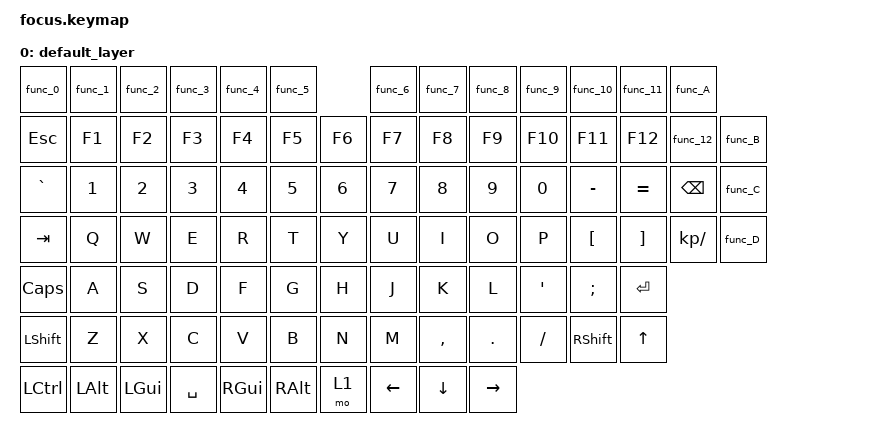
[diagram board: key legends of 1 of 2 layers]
#include <behaviors.dtsi>
#include <dt-bindings/zmk/keys.h>
#include <dt-bindings/zmk/bt.h>

/ {
    macros {
        zed_em_kay: zed_em_kay {
            compatible = "zmk,behavior-macro";
            #binding-cells = <0>;
            bindings
                = <&macro_press &kp LGUI>
                , <&macro_tap &kp N>
                , <&macro_release &kp LGUI>
                ;
        };
        func_0: func_0 {
            compatible = "zmk,behavior-macro";
            #binding-cells = <0>;
            bindings
                = <&macro_press &kp LSHIFT>
                , <&macro_press &kp LCTRL>
                , <&macro_press &kp LALT>
                , <&macro_tap &kp R>
                , <&macro_release &kp LSHIFT>
                , <&macro_release &kp LCTRL>
                , <&macro_release &kp LALT>
                ;
        };
        func_1: func_1 {
            compatible = "zmk,behavior-macro";
            #binding-cells = <0>;
            bindings
                = <&macro_press &kp LSHIFT>
                , <&macro_press &kp LCTRL>
                , <&macro_press &kp LALT>
                , <&macro_tap &kp T>
                , <&macro_release &kp LSHIFT>
                , <&macro_release &kp LCTRL>
                , <&macro_release &kp LALT>
                ;
        };
        func_2: func_2 {
            compatible = "zmk,behavior-macro";
            #binding-cells = <0>;
            bindings
                = <&macro_press &kp LSHIFT>
                , <&macro_press &kp LCTRL>
                , <&macro_press &kp LALT>
                , <&macro_tap &kp Y>
                , <&macro_release &kp LSHIFT>
                , <&macro_release &kp LCTRL>
                , <&macro_release &kp LALT>
                ;
        };
        func_3: func_3 {
            compatible = "zmk,behavior-macro";
            #binding-cells = <0>;
            bindings
                = <&macro_press &kp LSHIFT>
                , <&macro_press &kp LCTRL>
                , <&macro_press &kp LALT>
                , <&macro_tap &kp U>
                , <&macro_release &kp LSHIFT>
                , <&macro_release &kp LCTRL>
                , <&macro_release &kp LALT>
                ;
        };
        func_4: func_4 {
            compatible = "zmk,behavior-macro";
            #binding-cells = <0>;
            bindings
                = <&macro_press &kp LSHIFT>
                , <&macro_press &kp LCTRL>
                , <&macro_press &kp LALT>
                , <&macro_tap &kp I>
                , <&macro_release &kp LSHIFT>
                , <&macro_release &kp LCTRL>
                , <&macro_release &kp LALT>
                ;
        };
        func_5: func_5 {
            compatible = "zmk,behavior-macro";
            #binding-cells = <0>;
            bindings
                = <&macro_press &kp LSHIFT>
                , <&macro_press &kp LCTRL>
                , <&macro_press &kp LALT>
                , <&macro_tap &kp O>
                , <&macro_release &kp LSHIFT>
                , <&macro_release &kp LCTRL>
                , <&macro_release &kp LALT>
                ;
        };
        func_6: func_6 {
            compatible = "zmk,behavior-macro";
            #binding-cells = <0>;
            bindings
                = <&macro_press &kp LSHIFT>
                , <&macro_press &kp LCTRL>
                , <&macro_press &kp LALT>
                , <&macro_tap &kp F>
                , <&macro_release &kp LSHIFT>
                , <&macro_release &kp LCTRL>
                , <&macro_release &kp LALT>
                ;
        };
        func_7: func_7 {
            compatible = "zmk,behavior-macro";
            #binding-cells = <0>;
            bindings
                = <&macro_press &kp LSHIFT>
                , <&macro_press &kp LCTRL>
                , <&macro_press &kp LALT>
                , <&macro_tap &kp G>
                , <&macro_release &kp LSHIFT>
                , <&macro_release &kp LCTRL>
                , <&macro_release &kp LALT>
                ;
        };
        func_8: func_8 {
            compatible = "zmk,behavior-macro";
            #binding-cells = <0>;
            bindings
                = <&macro_press &kp LSHIFT>
                , <&macro_press &kp LCTRL>
                , <&macro_press &kp LALT>
                , <&macro_tap &kp H>
                , <&macro_release &kp LSHIFT>
                , <&macro_release &kp LCTRL>
                , <&macro_release &kp LALT>
                ;
        };
        func_9: func_9 {
            compatible = "zmk,behavior-macro";
            #binding-cells = <0>;
            bindings
                = <&macro_press &kp LSHIFT>
                , <&macro_press &kp LCTRL>
                , <&macro_press &kp LALT>
                , <&macro_tap &kp J>
                , <&macro_release &kp LSHIFT>
                , <&macro_release &kp LCTRL>
                , <&macro_release &kp LALT>
                ;
        };
        func_10: func_10 {
            compatible = "zmk,behavior-macro";
            #binding-cells = <0>;
            bindings
                = <&macro_press &kp LSHIFT>
                , <&macro_press &kp LCTRL>
                , <&macro_press &kp LALT>
                , <&macro_tap &kp K>
                , <&macro_release &kp LSHIFT>
                , <&macro_release &kp LCTRL>
                , <&macro_release &kp LALT>
                ;
        };
        func_11: func_11 {
            compatible = "zmk,behavior-macro";
            #binding-cells = <0>;
            bindings
                = <&macro_press &kp LSHIFT>
                , <&macro_press &kp LCTRL>
                , <&macro_press &kp LALT>
                , <&macro_tap &kp L>
                , <&macro_release &kp LSHIFT>
                , <&macro_release &kp LCTRL>
                , <&macro_release &kp LALT>
                ;
        };
        func_12: func_12 {
            compatible = "zmk,behavior-macro";
            #binding-cells = <0>;
            bindings
                = <&macro_press &kp LSHIFT>
                , <&macro_press &kp LCTRL>
                , <&macro_press &kp LALT>
                , <&macro_tap &kp P>
                , <&macro_release &kp LSHIFT>
                , <&macro_release &kp LCTRL>
                , <&macro_release &kp LALT>
                ;
        };
        func_A: func_A {
            compatible = "zmk,behavior-macro";
            #binding-cells = <0>;
            bindings
                = <&macro_press &kp LSHIFT>
                , <&macro_press &kp LCTRL>
                , <&macro_press &kp LALT>
                , <&macro_tap &kp V>
                , <&macro_release &kp LSHIFT>
                , <&macro_release &kp LCTRL>
                , <&macro_release &kp LALT>
                ;
        };
        func_B: func_B {
            compatible = "zmk,behavior-macro";
            #binding-cells = <0>;
            bindings
                = <&macro_press &kp LSHIFT>
                , <&macro_press &kp LCTRL>
                , <&macro_press &kp LALT>
                , <&macro_tap &kp B>
                , <&macro_release &kp LSHIFT>
                , <&macro_release &kp LCTRL>
                , <&macro_release &kp LALT>
                ;
        };
        func_C: func_C {
            compatible = "zmk,behavior-macro";
            #binding-cells = <0>;
            bindings
                = <&macro_press &kp LSHIFT>
                , <&macro_press &kp LCTRL>
                , <&macro_press &kp LALT>
                , <&macro_tap &kp N>
                , <&macro_release &kp LSHIFT>
                , <&macro_release &kp LCTRL>
                , <&macro_release &kp LALT>
                ;
        };
        func_D: func_D {
            compatible = "zmk,behavior-macro";
            #binding-cells = <0>;
            bindings
                = <&macro_press &kp LSHIFT>
                , <&macro_press &kp LCTRL>
                , <&macro_press &kp LALT>
                , <&macro_tap &kp M>
                , <&macro_release &kp LSHIFT>
                , <&macro_release &kp LCTRL>
                , <&macro_release &kp LALT>
                ;
        };
    };
};


/ {
    keymap {
        compatible = "zmk,keymap";

        default_layer {
            bindings = <
                &func_0    &func_1      &func_2       &func_3       &func_4       &func_5       &func_6       &func_7       &func_8       &func_9       &func_10     &func_11     &func_A
                
                &kp ESC     &kp F1      &kp F2      &kp F3      &kp F4      &kp F5      &kp F6      &kp F7      &kp F8      &kp F9      &kp F10     &kp F11      &kp F12    &func_12     &func_B
                
                &kp GRAVE   &kp NUMBER_1       &kp NUMBER_2       &kp NUMBER_3       &kp NUMBER_4       &kp NUMBER_5       &kp NUMBER_6       &kp NUMBER_7       &kp NUMBER_8       &kp NUMBER_9       &kp NUMBER_0       &kp MINUS    &kp EQUAL   &kp BSPC     &func_C
                
                &kp TAB     &kp Q       &kp W       &kp E       &kp R       &kp T       &kp Y       &kp U       &kp I       &kp O       &kp P       &kp LBKT     &kp RBKT    &kp KP_SLASH    &func_D
                
                &kp CAPS    &kp A       &kp S       &kp D       &kp F       &kp G       &kp H       &kp J       &kp K       &kp L       &kp SQT     &kp SEMI     &kp ENTER
                
                &kp LSHFT   &kp Z       &kp X       &kp C       &kp V       &kp B       &kp N       &kp M       &kp COMMA   &kp DOT     &kp SLASH   &kp RSHFT    &kp UP
                
                &kp LCTRL   &kp LALT    &kp LGUI    &kp SPACE   &kp RGUI    &kp RALT    &mo 1   &kp LEFT    &kp DOWN    &kp RIGHT
            >;
        };
        
        /* layer 1 */
        bt_layer {
            bindings = <
                &bt BT_SEL 0      &bt BT_SEL 1     &bt BT_SEL 2     &bt BT_SEL 3     &bt BT_SEL 4     &bt BT_CLR
            >;
        };
    };
};
